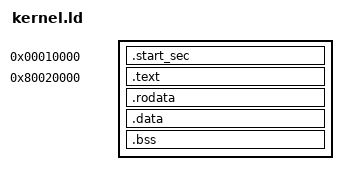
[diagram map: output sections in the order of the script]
/* the output binary will be elf 32 bit little end arm */
OUTPUT_FORMAT("elf32-littlearm")

/* output architecture arm */
OUTPUT_ARCH(arm)

/* define the entry point  */
/* tells teh linkre where execution ebgins */
ENTRY(_start)

/* reserve 4kb for supervisor stack svc */
ENTRY_SVC_STACK_SIZE = 0x1000;


/* defines how object files are palced in memory */
SECTIONS
{
  /* the entry point, before enabling paging. The code to enable paing
   needs to have the same virtual/physical address. entry.S and start.c
   run in this initial setting.*/

   /* sets the current link address to this thats where pi firmware loads the kernel */
  . = 0x10000;

  /* special section containint the first stage of kernel (startup codde before paging) */
  .start_sec : {

    /* starts with entry and start */
    build/entry.o(.text)
    build/start.o(.text .text.*)


    build/entry.o(.rodata .rodata.*)
    build/start.o(.rodata .rodata.*)

    build/entry.o(.data .data.*)
    build/start.o(.data .data.*)

    PROVIDE(edata_entry = .);

    build/entry.o(.bss .bss.* COMMON)
    build/start.o(.bss .bss.* COMMON)

    /*define a stack for the entry*/
    . = ALIGN(0x1000);
    . += ENTRY_SVC_STACK_SIZE;

    PROVIDE (svc_stktop = .);

    /* define the kernel page table, must be 16K and 16K-aligned*/
    . = ALIGN(0x4000);
    PROVIDE (_kernel_pgtbl = .);
    . += 0x4000;

    /* we also need a user page table*/
    PROVIDE (_user_pgtbl = .);
    . += 0x1000;

    PROVIDE(end_entry = .);
  }

  /*the kernel executes at the higher 2GB address space, but loaded
   at the lower memory (0x20000)*/
  . = 0x80020000;

  .text : AT(0x20000){
    *(.text .text.* .gnu.linkonce.t.*)
  }

  PROVIDE(etext = .);	/* Define the 'etext' symbol to this value */

  .rodata : {
    *(.rodata .rodata.* .gnu.linkonce.r.*)
  }

  /* aligned the data to a (4K) page, so it can be assigned
   different protection than the code*/
  . = ALIGN(0x1000);

  PROVIDE (data_start = .);

  .data : {
    *(.data .data.*)
  }

  PROVIDE (edata = .);

  .bss : {
    *(.bss .bss.* COMMON)
  }

  . = ALIGN(0x1000);
  PROVIDE (end = .);
}






/* 

Great question 👍 You’re looking at a **linker script** (`.ld`) for xv6 adapted to run on the Raspberry Pi (ARM).
This script tells the GNU linker (`ld`) **where to place code, data, and symbols** in memory.

Let’s break it down conceptually and then line by line.

---

## 🔹 Big Picture: Why a Linker Script?

* In normal programs, the compiler + linker decide memory layout automatically (text, data, heap, stack).
* For an OS kernel or bare-metal system, **you must explicitly control memory layout** because:

  * You decide the entry point address.
  * You must map virtual ↔ physical addresses.
  * You must reserve memory for special regions (stacks, page tables).
  * You must ensure alignment for the MMU and hardware requirements.

So this linker script defines:

1. **Entry point (\_start)**.
2. **Sections (text, rodata, data, bss)** and where they go.
3. **Special symbols** like `etext`, `edata`, `end`, `svc_stktop`.
4. **Initial physical loading vs virtual execution addresses.**

---

## 🔹 Top Part

```ld
OUTPUT_FORMAT("elf32-littlearm")
OUTPUT_ARCH(arm)
ENTRY(_start)
```

* **OUTPUT\_FORMAT**: The binary will be ELF, 32-bit, little-endian ARM.
* **OUTPUT\_ARCH**: Target CPU = ARM.
* **ENTRY(\_start)**: The first instruction after reset. Tells the linker where execution begins.

```ld
ENTRY_SVC_STACK_SIZE = 0x1000;
```

* Reserve 4 KB for the **SVC (supervisor) mode stack**. ARM has different stack pointers for each CPU mode.

---

## 🔹 Section Definitions

Linker scripts are a sequence of **SECTIONS { … }** that describe how object files (`.o`) are placed in memory.

---

### 1. Bootloader / Entry Stage (before paging)

```ld
. = 0x10000;
.start_sec : {
  build/entry.o(.text)
  build/start.o(.text .text.*)

  build/entry.o(.rodata .rodata.*)
  build/start.o(.rodata .rodata.*)

  build/entry.o(.data .data.*)
  build/start.o(.data .data.*)

  PROVIDE(edata_entry = .);

  build/entry.o(.bss .bss.* COMMON)
  build/start.o(.bss .bss.* COMMON)
```

* **`.` = 0x10000**: Set the current link address to **physical 0x10000** (64 KB). That’s where the Pi firmware loads the kernel.
* **.start\_sec**: Special section containing the first stage of kernel (startup code before paging).
* `entry.o` and `start.o`: Placed here because these files contain reset vectors, low-level init, MMU enabling code.
* `.rodata`, `.data`, `.bss`: For those files only (not the whole kernel).
* **`edata_entry`**: Marks the end of initialized data for the entry section.

---

### 2. Stack for entry mode

```ld
. = ALIGN(0x1000);
. += ENTRY_SVC_STACK_SIZE;
PROVIDE (svc_stktop = .);
```

* Align to 4 KB boundary.
* Add 4 KB for the supervisor stack.
* Define symbol `svc_stktop` = top of stack (the first usable address after the stack).
* Boot code will load SP = `svc_stktop`.

---

### 3. Page tables

```ld
. = ALIGN(0x4000);
PROVIDE (_kernel_pgtbl = .);
. += 0x4000;

PROVIDE (_user_pgtbl = .);
. += 0x1000;

PROVIDE(end_entry = .);
```

* Page tables must be **aligned and sized correctly** for ARM MMU.
* **Kernel page table**: 16 KB (0x4000).
* **User page table**: 4 KB (0x1000).
* `end_entry`: Symbol marking the end of entry section.

This all runs before virtual memory is enabled.

---

### 4. Kernel proper (after paging enabled)

```ld
. = 0x80020000;

.text : AT(0x20000){
  *(.text .text.* .gnu.linkonce.t.*)
}
```

* **Virtual address = 0x80020000**. Kernel is linked to run in the top half of address space (2 GB region).
* **AT(0x20000)**: Physical load address = 0x20000. Means:

  * Code is stored in RAM starting at 0x20000.
  * But when MMU is enabled, it will appear at 0x80020000.
* `.text`: Place all functions (`.text.*`) here.
* `etext` symbol marks the end of code.

---

### 5. Read-only data

```ld
.rodata : {
  *(.rodata .rodata.* .gnu.linkonce.r.*)
}
```

* Constant data (strings, lookup tables).
* Follows code.

---

### 6. Data and BSS

```ld
. = ALIGN(0x1000);
PROVIDE (data_start = .);

.data : {
  *(.data .data.*)
}
PROVIDE (edata = .);

.bss : {
  *(.bss .bss.* COMMON)
}

. = ALIGN(0x1000);
PROVIDE (end = .);
```

* `.data`: Initialized global/static variables.
* `edata`: End of initialized data.
* `.bss`: Uninitialized global/static vars → zeroed at runtime.
* `end`: End of kernel image (used for heap start).

---

## 🔹 Summary of Key Addresses

* `0x10000`: Startup code (entry.S, start.c).
* `svc_stktop`: Boot stack (4 KB).
* `_kernel_pgtbl`: 16 KB kernel page table.
* `_user_pgtbl`: 4 KB user page table.
* `0x80020000`: Kernel virtual base (linked here).
* `0x20000`: Kernel physical load address.
* `etext`: End of kernel code.
* `edata`: End of kernel data.
* `end`: End of kernel memory image.

---

✅ **Conceptually**:

* First section (`.start_sec`) = **real-mode boot code** running at the same physical and virtual address.
* Then define **stack + page tables** so you can safely enable the MMU.
* After enabling paging, kernel runs in high memory (`0x80020000` virtual), while still physically sitting at `0x20000`.
* Symbols like `etext`, `edata`, `end` are exported for C code to use (e.g., memory allocator initialization).

---

Do you want me to also **draw a memory layout diagram** showing where each section lands (physical vs virtual)? That might make it much clearer.



*/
